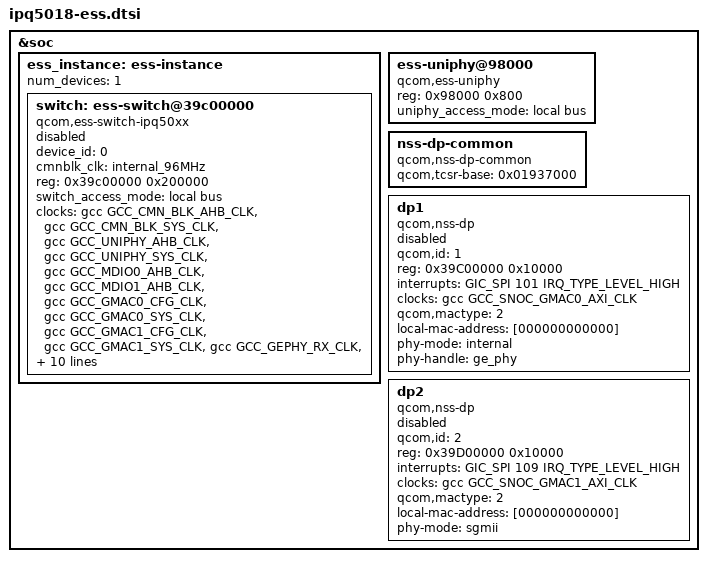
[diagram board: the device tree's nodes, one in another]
#include <dt-bindings/net/qcom-ipq-ess.h>

&soc {
	ess_instance: ess-instance {
		#address-cells = <1>;
		#size-cells = <1>;
		num_devices = <1>;

		switch: ess-switch@39c00000 {
			compatible = "qcom,ess-switch-ipq50xx";
			device_id = <0>;
			cmnblk_clk = "internal_96MHz";
			reg = <0x39c00000 0x200000>;
			switch_access_mode = "local bus";
			clocks = <&gcc GCC_CMN_BLK_AHB_CLK>,
				 <&gcc GCC_CMN_BLK_SYS_CLK>,
				 <&gcc GCC_UNIPHY_AHB_CLK>,
				 <&gcc GCC_UNIPHY_SYS_CLK>,
				 <&gcc GCC_MDIO0_AHB_CLK>,
				 <&gcc GCC_MDIO1_AHB_CLK>,
				 <&gcc GCC_GMAC0_CFG_CLK>,
				 <&gcc GCC_GMAC0_SYS_CLK>,
				 <&gcc GCC_GMAC1_CFG_CLK>,
				 <&gcc GCC_GMAC1_SYS_CLK>,
				 <&gcc GCC_GEPHY_RX_CLK>,
				 <&gcc GCC_GEPHY_TX_CLK>,
				 <&gcc GCC_UNIPHY_RX_CLK>,
				 <&gcc GCC_UNIPHY_TX_CLK>,
				 <&gcc GCC_GMAC0_RX_CLK>,
				 <&gcc GCC_GMAC0_TX_CLK>,
				 <&gcc GCC_GMAC1_RX_CLK>,
				 <&gcc GCC_GMAC1_TX_CLK>,
				 <&gcc GCC_SNOC_GMAC0_AHB_CLK>,
				 <&gcc GCC_SNOC_GMAC1_AHB_CLK>,
				 <&gcc GCC_GMAC0_PTP_CLK>,
				 <&gcc GCC_GMAC1_PTP_CLK>;
			clock-names = "cmn_ahb_clk",
				      "cmn_sys_clk",
				      "uniphy_ahb_clk",
				      "uniphy_sys_clk",
				      "gcc_mdio0_ahb_clk",
				      "gcc_mdio1_ahb_clk",
				      "gcc_gmac0_cfg_clk",
				      "gcc_gmac0_sys_clk",
				      "gcc_gmac1_cfg_clk",
				      "gcc_gmac1_sys_clk",
				      "uniphy0_port1_rx_clk",
				      "uniphy0_port1_tx_clk",
				      "uniphy1_port5_rx_clk",
				      "uniphy1_port5_tx_clk",
				      "nss_port1_rx_clk",
				      "nss_port1_tx_clk",
				      "nss_port2_rx_clk",
				      "nss_port2_tx_clk",
				      "gcc_snoc_gmac0_ahb_clk",
				      "gcc_snoc_gmac1_ahb_clk",
				      "gcc_gmac0_ptp_clk",
				      "gcc_gmac1_ptp_clk";
			resets = <&gcc GCC_GMAC0_BCR>,
				 <&gcc GCC_GMAC1_BCR>,
				 <&gcc GCC_UNIPHY_BCR>,
				 <&gcc GCC_UNIPHY_SOFT_RESET>;
			reset-names = "gmac0_bcr_rst",
				      "gmac1_bcr_rst",
				      "uniphy_bcr_rst",
				      "uniphy1_soft_rst";

			status = "disabled";
		};
	};

	ess-uniphy@98000 {
		compatible = "qcom,ess-uniphy";
		reg = <0x98000 0x800>;
		uniphy_access_mode = "local bus";
	};

	nss-dp-common {
		compatible = "qcom,nss-dp-common";
		qcom,tcsr-base = <0x01937000>;
	};

	dp1: dp1 {
		device_type = "network";
		compatible = "qcom,nss-dp";
		qcom,id = <1>;

		reg = <0x39C00000 0x10000>;
		interrupts = <GIC_SPI 101 IRQ_TYPE_LEVEL_HIGH>;
		clocks = <&gcc GCC_SNOC_GMAC0_AXI_CLK>;
		clock-names = "nss-snoc-gmac-axi-clk";

		qcom,mactype = <2>; /* GMAC_HAL_TYPE_SYN_GMAC */
		local-mac-address = [000000000000];
		phy-mode = "internal";
		phy-handle = <&ge_phy>;

		status = "disabled";
	};

	dp2: dp2 {
		device_type = "network";
		compatible = "qcom,nss-dp";
		qcom,id = <2>;

		reg = <0x39D00000 0x10000>;
		interrupts = <GIC_SPI 109 IRQ_TYPE_LEVEL_HIGH>;
		clocks = <&gcc GCC_SNOC_GMAC1_AXI_CLK>;
		clock-names = "nss-snoc-gmac-axi-clk";

		qcom,mactype = <2>; /* GMAC_HAL_TYPE_SYN_GMAC */
		local-mac-address = [000000000000];
		phy-mode = "sgmii";
		status = "disabled";
	};
};
